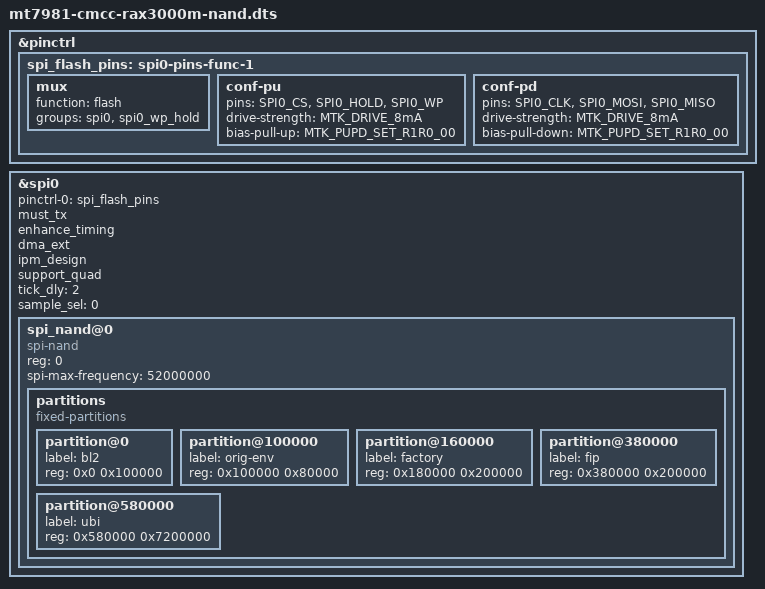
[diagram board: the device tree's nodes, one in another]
// SPDX-License-Identifier: GPL-2.0-only

/dts-v1/;
#include "mt7981-cmcc-rax3000m.dtsi"

&pinctrl {
	spi_flash_pins: spi0-pins-func-1 {
		mux {
			function = "flash";
			groups = "spi0", "spi0_wp_hold";
		};

		conf-pu {
			pins = "SPI0_CS", "SPI0_HOLD", "SPI0_WP";
			drive-strength = <MTK_DRIVE_8mA>;
			bias-pull-up = <MTK_PUPD_SET_R1R0_00>;
		};

		conf-pd {
			pins = "SPI0_CLK", "SPI0_MOSI", "SPI0_MISO";
			drive-strength = <MTK_DRIVE_8mA>;
			bias-pull-down = <MTK_PUPD_SET_R1R0_00>;
		};
	};
};

&spi0 {
	#address-cells = <1>;
	#size-cells = <0>;
	pinctrl-names = "default";
	pinctrl-0 = <&spi_flash_pins>;
	status = "okay";
	must_tx;
	enhance_timing;
	dma_ext;
	ipm_design;
	support_quad;
	tick_dly = <2>;
	sample_sel = <0>;

	spi_nand@0 {
		compatible = "spi-nand";
		reg = <0>;
		spi-max-frequency = <52000000>;

		partitions {
			compatible = "fixed-partitions";
			#address-cells = <1>;
			#size-cells = <1>;

			partition@0 {
				label = "bl2";
				reg = <0x0 0x100000>;
			};

			partition@100000 {
				label = "orig-env";
				reg = <0x100000 0x80000>;
			};

			partition@160000 {
				label = "factory";
				reg = <0x180000 0x200000>;
			};

			partition@380000 {
				label = "fip";
				reg = <0x380000 0x200000>;
			};

			partition@580000 {
				label = "ubi";
				reg = <0x580000 0x7200000>;
			};
		};
	};
};
